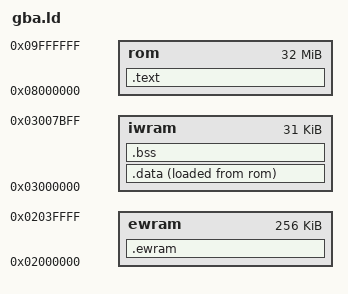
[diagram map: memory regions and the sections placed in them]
/* ROM at 0x08000000; variables in IWRAM (32 KB, fast), stacks at its top. */
OUTPUT_FORMAT("elf32-littlearm")
OUTPUT_ARCH(arm)
ENTRY(_start)

MEMORY {
    rom   : ORIGIN = 0x08000000, LENGTH = 32M
    ewram : ORIGIN = 0x02000000, LENGTH = 256K
    iwram : ORIGIN = 0x03000000, LENGTH = 31K
}

SECTIONS {
    .text : {
        KEEP(*(.crt0))
        *(.text .text.*)
        *(.rodata .rodata.*)
        . = ALIGN(4);
    } > rom

    .data : {
        __data_start = .;
        *(.data .data.*)
        *(.iwram .iwram.*)
        . = ALIGN(4);
        __data_end = .;
    } > iwram AT > rom
    __data_lma = LOADADDR(.data);

    .bss (NOLOAD) : {
        __bss_start = .;
        *(.bss .bss.*)
        *(COMMON)
        . = ALIGN(4);
        __bss_end = .;
    } > iwram

    .ewram (NOLOAD) : { *(.ewram .ewram.*) } > ewram

    /DISCARD/ : { *(.ARM.exidx*) *(.ARM.extab*) }
}
